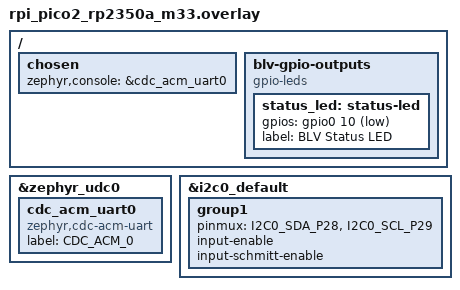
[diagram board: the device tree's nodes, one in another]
/*
 * USB CDC ACM virtual UART for the Raspberry Pi Pico 2.
 */
#include <zephyr/dt-bindings/gpio/gpio.h>

/ {
    chosen {
        zephyr,console = &cdc_acm_uart0;
    };

    blv-gpio-outputs {
        compatible = "gpio-leds";

        status_led: status-led {
            gpios = <&gpio0 10 GPIO_ACTIVE_LOW>;
            label = "BLV Status LED";
        };
    };
};

&zephyr_udc0 {
    status = "okay";

    cdc_acm_uart0: cdc_acm_uart0 {
        compatible = "zephyr,cdc-acm-uart";
        label = "CDC_ACM_0";
    };
};

&i2c0_default {
    group1 {
        pinmux = <I2C0_SDA_P28>, <I2C0_SCL_P29>;
        input-enable;
        input-schmitt-enable;
    };
};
